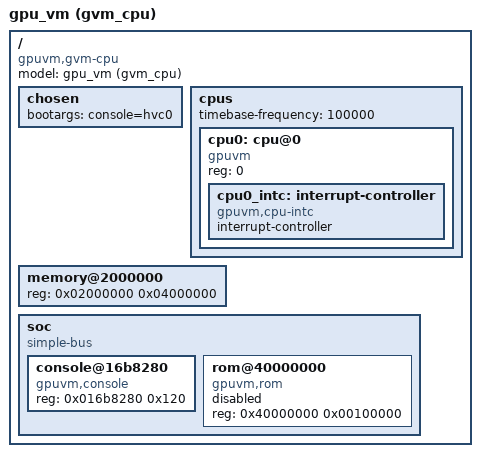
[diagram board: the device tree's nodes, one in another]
// SPDX-License-Identifier: GPL-2.0
/*
 * gpu_vm on gvm_cpu (gpu_vm/linux/README.md): one core, RAM from 0x02000000 (64 MB: gvm_cpu's default --ram; change
 * the memory node with --ram), the console's words in the device window. Loaded by gvm_cpu --dtb at 0x1000.
 */
/dts-v1/;

/ {
	#address-cells = <1>;
	#size-cells = <1>;
	compatible = "gpuvm,gvm-cpu";
	model = "gpu_vm (gvm_cpu)";

	chosen {
		bootargs = "console=hvc0";
	};

	cpus {
		#address-cells = <1>;
		#size-cells = <0>;
		/* TIME and TCMP count at 100 kHz */
		timebase-frequency = <100000>;

		cpu0: cpu@0 {
			device_type = "cpu";
			compatible = "gpuvm";
			reg = <0>;

			/* IEN and IPEND: 0 software, 1 timer, 2 external */
			cpu0_intc: interrupt-controller {
				compatible = "gpuvm,cpu-intc";
				interrupt-controller;
				#interrupt-cells = <1>;
			};
		};
	};

	memory@2000000 {
		device_type = "memory";
		reg = <0x02000000 0x04000000>;
	};

	soc {
		#address-cells = <1>;
		#size-cells = <1>;
		compatible = "simple-bus";
		ranges;

		/* The host's words at +0, the guest's at +0x10, the output ring (256 bytes) at +0x20 */
		console@16b8280 {
			compatible = "gpuvm,console";
			reg = <0x016b8280 0x120>;
		};

		/* The ROM as the disk gvmrom: the size is the image's (gvm_cpu --rom); disabled until it is known */
		rom@40000000 {
			compatible = "gpuvm,rom";
			reg = <0x40000000 0x00100000>;
			status = "disabled";
		};
	};
};
